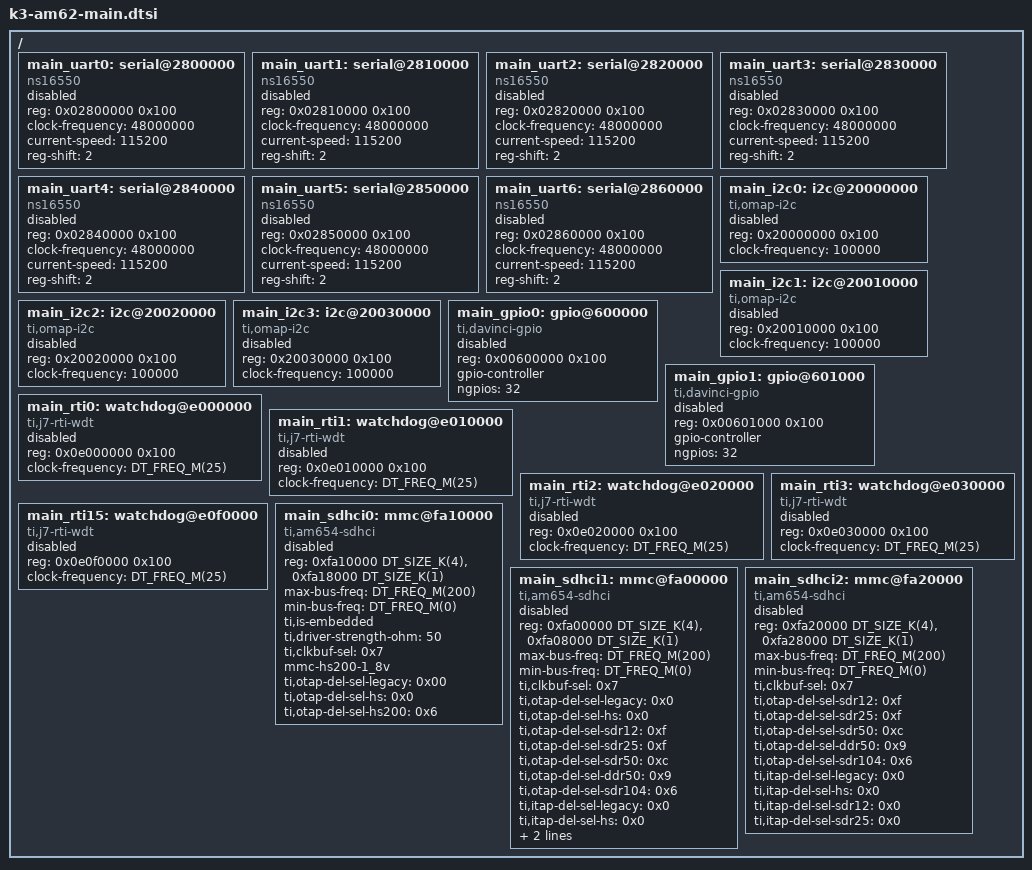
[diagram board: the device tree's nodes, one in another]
/*
 * Device Tree Source for AM625 SoC Family Main Domain peripherals
 *
 * Copyright (c) 2025 Ayush Singh, BeagleBoard.org Foundation
 *
 * SPDX-License-Identifier: Apache-2.0
 */

/ {
	main_uart0: serial@2800000 {
		compatible = "ns16550";
		reg = <0x02800000 0x100>;
		clock-frequency = <48000000>;
		current-speed = <115200>;
		reg-shift = <2>;
		status = "disabled";
	};

	main_uart1: serial@2810000 {
		compatible = "ns16550";
		reg = <0x02810000 0x100>;
		clock-frequency = <48000000>;
		current-speed = <115200>;
		reg-shift = <2>;
		status = "disabled";
	};

	main_uart2: serial@2820000 {
		compatible = "ns16550";
		reg = <0x02820000 0x100>;
		clock-frequency = <48000000>;
		current-speed = <115200>;
		reg-shift = <2>;
		status = "disabled";
	};

	main_uart3: serial@2830000 {
		compatible = "ns16550";
		reg = <0x02830000 0x100>;
		clock-frequency = <48000000>;
		current-speed = <115200>;
		reg-shift = <2>;
		status = "disabled";
	};

	main_uart4: serial@2840000 {
		compatible = "ns16550";
		reg = <0x02840000 0x100>;
		clock-frequency = <48000000>;
		current-speed = <115200>;
		reg-shift = <2>;
		status = "disabled";
	};

	main_uart5: serial@2850000 {
		compatible = "ns16550";
		reg = <0x02850000 0x100>;
		clock-frequency = <48000000>;
		current-speed = <115200>;
		reg-shift = <2>;
		status = "disabled";
	};

	main_uart6: serial@2860000 {
		compatible = "ns16550";
		reg = <0x02860000 0x100>;
		clock-frequency = <48000000>;
		current-speed = <115200>;
		reg-shift = <2>;
		status = "disabled";
	};

	main_i2c0: i2c@20000000 {
		compatible = "ti,omap-i2c";
		reg = <0x20000000 0x100>;
		clock-frequency = <100000>;
		#address-cells = <1>;
		#size-cells = <0>;
		status = "disabled";
	};

	main_i2c1: i2c@20010000 {
		compatible = "ti,omap-i2c";
		reg = <0x20010000 0x100>;
		clock-frequency = <100000>;
		#address-cells = <1>;
		#size-cells = <0>;
		status = "disabled";
	};

	main_i2c2: i2c@20020000 {
		compatible = "ti,omap-i2c";
		reg = <0x20020000 0x100>;
		clock-frequency = <100000>;
		#address-cells = <1>;
		#size-cells = <0>;
		status = "disabled";
	};

	main_i2c3: i2c@20030000 {
		compatible = "ti,omap-i2c";
		reg = <0x20030000 0x100>;
		clock-frequency = <100000>;
		#address-cells = <1>;
		#size-cells = <0>;
		status = "disabled";
	};

	main_gpio0: gpio@600000 {
		compatible = "ti,davinci-gpio";
		reg = <0x00600000 0x100>;
		gpio-controller;
		#gpio-cells = <2>;
		/* FIXME: Enable all 92 GPIOs */
		ngpios = <32>;
		status = "disabled";
	};

	main_gpio1: gpio@601000 {
		compatible = "ti,davinci-gpio";
		reg = <0x00601000 0x100>;
		gpio-controller;
		#gpio-cells = <2>;
		/* FIXME: Enable all 52 GPIOs */
		ngpios = <32>;
		status = "disabled";
	};

	main_rti0: watchdog@e000000 {
		compatible = "ti,j7-rti-wdt";
		reg = <0x0e000000 0x100>;
		clock-frequency = <DT_FREQ_M(25)>;
		status = "disabled";
	};

	main_rti1: watchdog@e010000 {
		compatible = "ti,j7-rti-wdt";
		reg = <0x0e010000 0x100>;
		clock-frequency = <DT_FREQ_M(25)>;
		status = "disabled";
	};

	main_rti2: watchdog@e020000 {
		compatible = "ti,j7-rti-wdt";
		reg = <0x0e020000 0x100>;
		clock-frequency = <DT_FREQ_M(25)>;
		status = "disabled";
	};

	main_rti3: watchdog@e030000 {
		compatible = "ti,j7-rti-wdt";
		reg = <0x0e030000 0x100>;
		clock-frequency = <DT_FREQ_M(25)>;
		status = "disabled";
	};

	main_rti15: watchdog@e0f0000 {
		compatible = "ti,j7-rti-wdt";
		reg = <0x0e0f0000 0x100>;
		clock-frequency = <DT_FREQ_M(25)>;
		status = "disabled";
	};

	main_sdhci0: mmc@fa10000 {
		compatible = "ti,am654-sdhci";
		reg = <0xfa10000 DT_SIZE_K(4)>, <0xfa18000 DT_SIZE_K(1)>;
		reg-names = "host", "subsys";
		max-bus-freq = <DT_FREQ_M(200)>;
		min-bus-freq = <DT_FREQ_M(0)>;
		ti,is-embedded;
		ti,driver-strength-ohm = <50>;
		ti,clkbuf-sel = <0x7>;
		mmc-hs200-1_8v;
		ti,otap-del-sel-legacy = <0x00>;
		ti,otap-del-sel-hs = <0x0>;
		ti,otap-del-sel-hs200 = <0x6>;
		status = "disabled";
	};

	main_sdhci1: mmc@fa00000 {
		compatible = "ti,am654-sdhci";
		reg = <0xfa00000 DT_SIZE_K(4)>, <0xfa08000 DT_SIZE_K(1)>;
		reg-names = "host", "subsys";
		max-bus-freq = <DT_FREQ_M(200)>;
		min-bus-freq = <DT_FREQ_M(0)>;
		ti,clkbuf-sel = <0x7>;
		ti,otap-del-sel-legacy = <0x0>;
		ti,otap-del-sel-hs = <0x0>;
		ti,otap-del-sel-sdr12 = <0xf>;
		ti,otap-del-sel-sdr25 = <0xf>;
		ti,otap-del-sel-sdr50 = <0xc>;
		ti,otap-del-sel-ddr50 = <0x9>;
		ti,otap-del-sel-sdr104 = <0x6>;
		ti,itap-del-sel-legacy = <0x0>;
		ti,itap-del-sel-hs = <0x0>;
		ti,itap-del-sel-sdr12 = <0x0>;
		ti,itap-del-sel-sdr25 = <0x0>;
		status = "disabled";
	};

	main_sdhci2: mmc@fa20000 {
		compatible = "ti,am654-sdhci";
		reg = <0xfa20000 DT_SIZE_K(4)>, <0xfa28000 DT_SIZE_K(1)>;
		reg-names = "host", "subsys";
		max-bus-freq = <DT_FREQ_M(200)>;
		min-bus-freq = <DT_FREQ_M(0)>;
		ti,clkbuf-sel = <0x7>;
		ti,otap-del-sel-sdr12 = <0xf>;
		ti,otap-del-sel-sdr25 = <0xf>;
		ti,otap-del-sel-sdr50 = <0xc>;
		ti,otap-del-sel-ddr50 = <0x9>;
		ti,otap-del-sel-sdr104 = <0x6>;
		ti,itap-del-sel-legacy = <0x0>;
		ti,itap-del-sel-hs = <0x0>;
		ti,itap-del-sel-sdr12 = <0x0>;
		ti,itap-del-sel-sdr25 = <0x0>;
		status = "disabled";
	};
};
